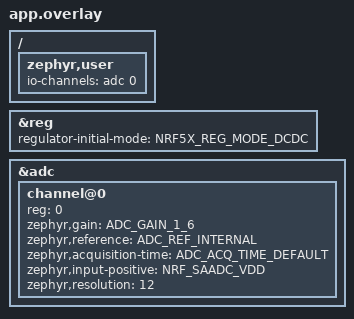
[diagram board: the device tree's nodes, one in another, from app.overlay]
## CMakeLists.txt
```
cmake_minimum_required(VERSION 3.20.0)
find_package(Zephyr REQUIRED HINTS $ENV{ZEPHYR_BASE})
project(sentorin_pen)
target_sources(app PRIVATE src/main.c)
```

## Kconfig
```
source "Kconfig.zephyr"

config SENTORIN_PUBLIC_ID
	string "Fallback device public ID (used when UICR is not programmed)"
	default "DEV00001"

config SENTORIN_ADV_INTERVAL_MS
	int "Advertising interval, ms"
	default 2000

config SENTORIN_LOW_BATT_MV
	int "Below this supply voltage, advertise 5x slower"
	default 2100
```

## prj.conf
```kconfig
# Bluetooth: scannable, non-connectable beacon
CONFIG_BT=y
CONFIG_BT_BROADCASTER=y
CONFIG_BT_DEVICE_NAME="STN"
CONFIG_BT_EXT_ADV=n

# BC832 has no 32.768 kHz crystal on this board: internal RC with calibration
CONFIG_CLOCK_CONTROL_NRF_K32SRC_RC=y
CONFIG_CLOCK_CONTROL_NRF_K32SRC_500PPM=y

# Battery measurement (SAADC, internal VDD input)
CONFIG_ADC=y

# Power: no console, no logging, in production builds
CONFIG_PM_DEVICE=y
CONFIG_SERIAL=n
CONFIG_CONSOLE=n
CONFIG_UART_CONSOLE=n
CONFIG_LOG=n
CONFIG_GPIO=n
```

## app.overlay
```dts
/* BC832 V1 pen board: DC/DC inductors L1/L2 are fitted, so run the regulator in DC/DC mode. */
&reg {
	regulator-initial-mode = <NRF5X_REG_MODE_DCDC>;
};

/ {
	zephyr,user {
		io-channels = <&adc 0>;
	};
};

&adc {
	#address-cells = <1>;
	#size-cells = <0>;
	status = "okay";

	channel@0 {
		reg = <0>;
		zephyr,gain = "ADC_GAIN_1_6";
		zephyr,reference = "ADC_REF_INTERNAL";
		zephyr,acquisition-time = <ADC_ACQ_TIME_DEFAULT>;
		zephyr,input-positive = <NRF_SAADC_VDD>;
		zephyr,resolution = <12>;
	};
};
```

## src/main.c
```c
/*
 * Sentorin pen firmware, v1 beacon.
 *
 * Advertises (scannable, non-connectable) so the owner's phone can find it:
 *   advertising data : flags, Sentorin 128-bit service UUID, manufacturer data = battery mV
 *   scan response    : complete name "STN-<public id>"
 * The phone app (app/src/PenScreen.tsx) filters on the UUID and matches the name.
 *
 * NOT YET IMPLEMENTED (see firmware/README.md): rotating private identifiers,
 * authenticated provisioning / ownership transfer, unwanted-tracking protections.
 */
#include <zephyr/kernel.h>
#include <zephyr/bluetooth/bluetooth.h>
#include <zephyr/bluetooth/uuid.h>
#include <zephyr/drivers/adc.h>
#include <nrfx.h>
#include <string.h>

#define SENTORIN_UUID BT_UUID_128_ENCODE(0x7e570001, 0x5a4e, 0x4f52, 0x8a11, 0x53454e544f52)
#define PUBLIC_ID_LEN 8
#define BATTERY_PERIOD K_MINUTES(10)
#define ADV_UNITS(ms) ((ms) * 1000 / 625)

static const struct adc_dt_spec vdd_adc = ADC_DT_SPEC_GET(DT_PATH(zephyr_user));

static char adv_name[4 + PUBLIC_ID_LEN + 1] = "STN-";
static uint8_t mfg_data[4] = { 0xff, 0xff, 0x00, 0x00 }; /* 0xFFFF = test company ID; then battery mV, little endian */

static const struct bt_data ad[] = {
	BT_DATA_BYTES(BT_DATA_FLAGS, BT_LE_AD_GENERAL | BT_LE_AD_NO_BREDR),
	BT_DATA_BYTES(BT_DATA_UUID128_ALL, SENTORIN_UUID),
	BT_DATA(BT_DATA_MANUFACTURER_DATA, mfg_data, sizeof(mfg_data)),
};
static struct bt_data sd[] = {
	BT_DATA(BT_DATA_NAME_COMPLETE, adv_name, 0), /* length filled in at start-up */
};

/* The public ID is written to UICR CUSTOMER[0..1] at the factory (8 ASCII characters). */
static void load_public_id(void)
{
	char id[PUBLIC_ID_LEN + 1] = { 0 };
	uint32_t words[2] = { NRF_UICR->CUSTOMER[0], NRF_UICR->CUSTOMER[1] };

	if (words[0] != 0xffffffff) {
		memcpy(id, words, PUBLIC_ID_LEN);
	} else {
		strncpy(id, CONFIG_SENTORIN_PUBLIC_ID, PUBLIC_ID_LEN);
	}
	strncat(adv_name, id, PUBLIC_ID_LEN);
	sd[0].data_len = strlen(adv_name);
}

static int read_vdd_mv(void)
{
	int16_t raw = 0;
	struct adc_sequence seq = { .buffer = &raw, .buffer_size = sizeof(raw) };
	int32_t mv;

	adc_sequence_init_dt(&vdd_adc, &seq);
	if (adc_read_dt(&vdd_adc, &seq) < 0) {
		return -1;
	}
	mv = raw;
	if (adc_raw_to_millivolts_dt(&vdd_adc, &mv) < 0) {
		return -1;
	}
	return mv;
}

static int start_adv(int interval_ms)
{
	struct bt_le_adv_param param = BT_LE_ADV_PARAM_INIT(BT_LE_ADV_OPT_SCANNABLE | BT_LE_ADV_OPT_USE_IDENTITY,
							    ADV_UNITS(interval_ms), ADV_UNITS(interval_ms) + 16, NULL);

	return bt_le_adv_start(&param, ad, ARRAY_SIZE(ad), sd, ARRAY_SIZE(sd));
}

int main(void)
{
	bool slow = false;

	load_public_id();
	if (!adc_is_ready_dt(&vdd_adc) || adc_channel_setup_dt(&vdd_adc) < 0) {
		return 0;
	}
	if (bt_enable(NULL) < 0) {
		return 0;
	}
	if (start_adv(CONFIG_SENTORIN_ADV_INTERVAL_MS) < 0) {
		return 0;
	}

	while (1) {
		int mv = read_vdd_mv();

		if (mv > 0) {
			bool want_slow = mv < CONFIG_SENTORIN_LOW_BATT_MV;

			mfg_data[2] = mv & 0xff;
			mfg_data[3] = (mv >> 8) & 0xff;
			if (want_slow != slow) {
				/* Nearly flat cells: advertise 5x less often to avoid brown-out resets. */
				slow = want_slow;
				bt_le_adv_stop();
				start_adv(CONFIG_SENTORIN_ADV_INTERVAL_MS * (slow ? 5 : 1));
			} else {
				bt_le_adv_update_data(ad, ARRAY_SIZE(ad), sd, ARRAY_SIZE(sd));
			}
		}
		k_sleep(BATTERY_PERIOD);
	}
	return 0;
}
```
